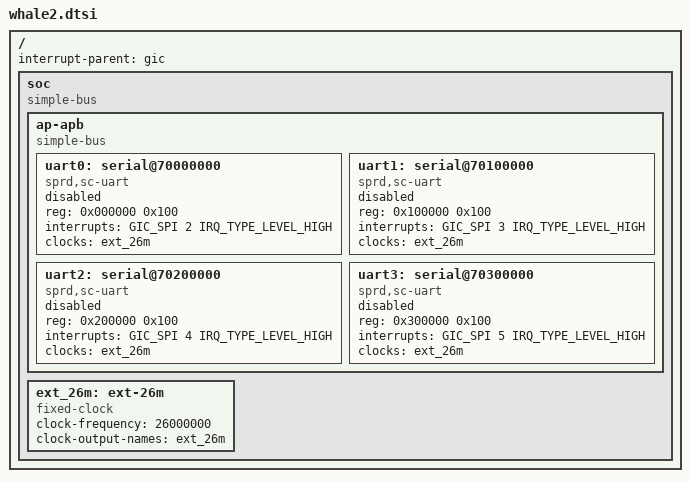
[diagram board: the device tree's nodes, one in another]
/*
 * Spreadtrum Whale2 SoC platform peripherals DTS file
 *
 * Copyright (C) 2016, Spreadtrum Communications Inc.
 *
 * This file is licensed under a dual GPLv2 or X11 license.
 */

/ {
	interrupt-parent = <&gic>;
	#address-cells = <2>;
	#size-cells = <2>;

	soc: soc {
		compatible = "simple-bus";
		#address-cells = <2>;
		#size-cells = <2>;
		ranges;

		ap-apb {
			compatible = "simple-bus";
			#address-cells = <1>;
			#size-cells = <1>;
			ranges = <0 0x0 0x70000000 0x10000000>;

			uart0: serial@70000000 {
				compatible = "sprd,sc-uart";
				reg = <0x000000 0x100>;
				interrupts = <GIC_SPI 2 IRQ_TYPE_LEVEL_HIGH>;
				clocks = <&ext_26m>;
				status = "disabled";
			};

			uart1: serial@70100000 {
				compatible = "sprd,sc-uart";
				reg = <0x100000 0x100>;
				interrupts = <GIC_SPI 3 IRQ_TYPE_LEVEL_HIGH>;
				clocks = <&ext_26m>;
				status = "disabled";
			};

			uart2: serial@70200000 {
				compatible = "sprd,sc-uart";
				reg = <0x200000 0x100>;
				interrupts = <GIC_SPI 4 IRQ_TYPE_LEVEL_HIGH>;
				clocks = <&ext_26m>;
				status = "disabled";
			};

			uart3: serial@70300000 {
				compatible = "sprd,sc-uart";
				reg = <0x300000 0x100>;
				interrupts = <GIC_SPI 5 IRQ_TYPE_LEVEL_HIGH>;
				clocks = <&ext_26m>;
				status = "disabled";
			};
		};

		ext_26m: ext-26m {
			compatible = "fixed-clock";
			#clock-cells = <0>;
			clock-frequency = <26000000>;
			clock-output-names = "ext_26m";
		};
	};
};
